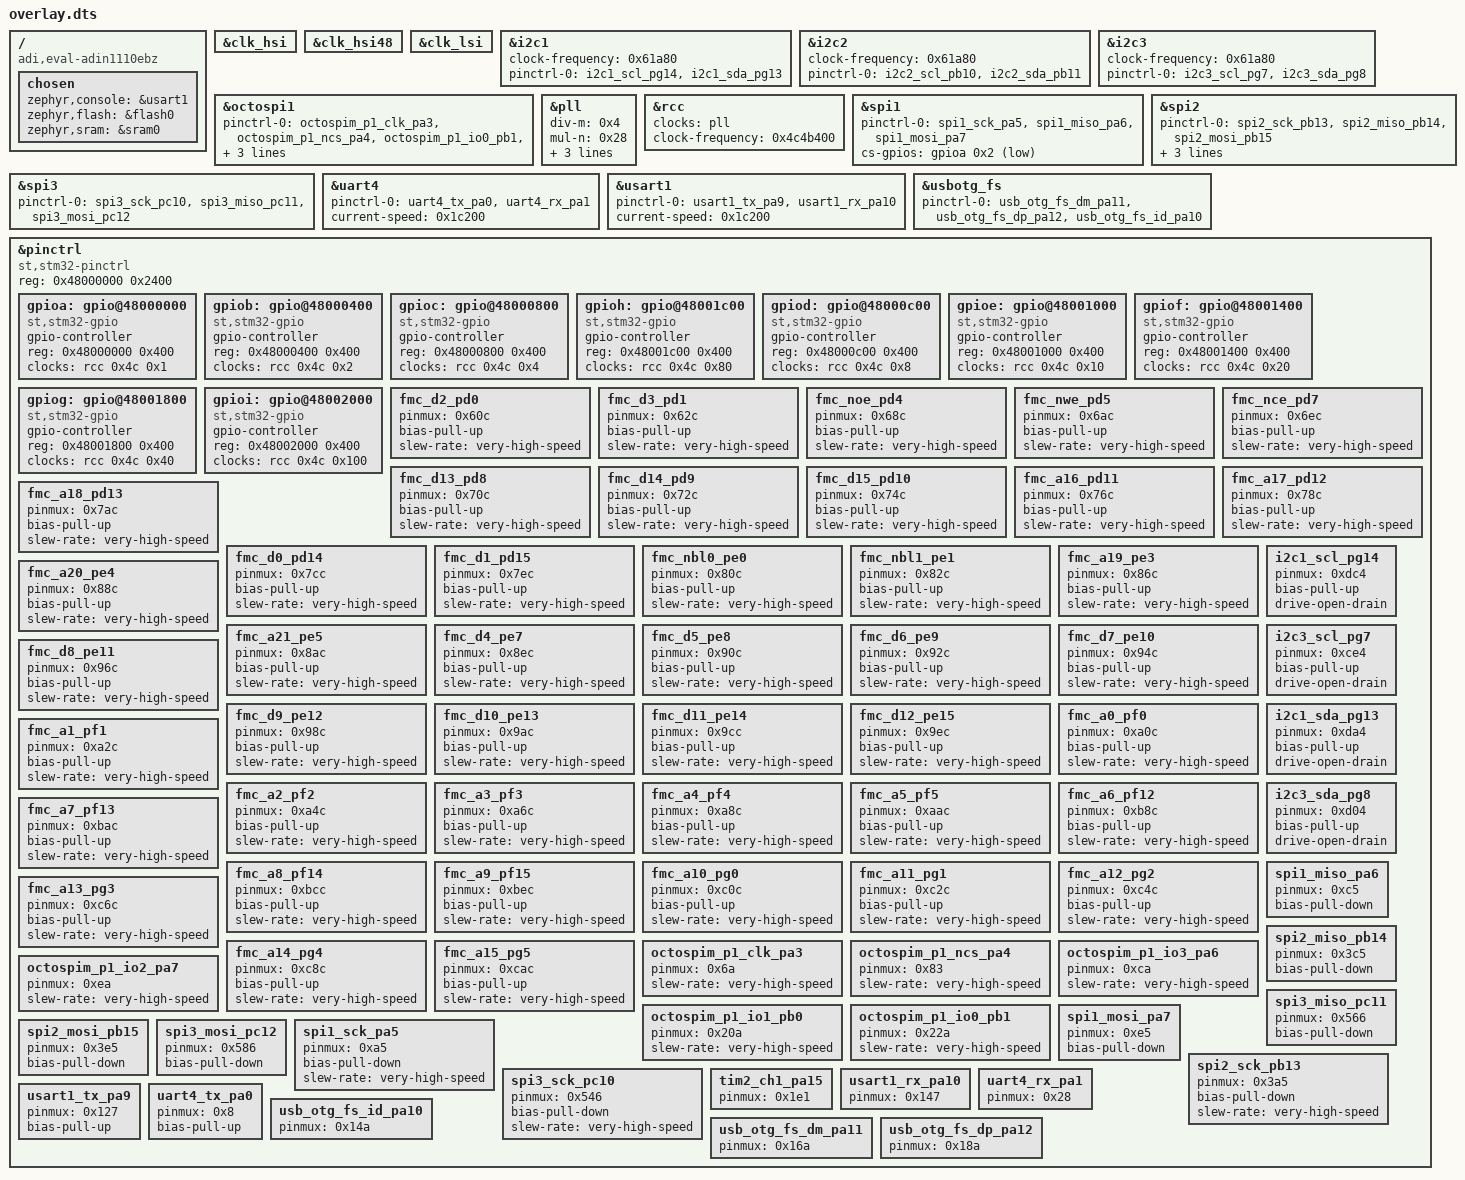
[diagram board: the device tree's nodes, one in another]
/ {
	compatible = "adi,eval-adin1110ebz";
	chosen {
		zephyr,console = &usart1;
		zephyr,flash = &flash0;
		zephyr,sram = &sram0;
	};
};
&clk_hsi{
	status = "okay";
};
&clk_hsi48{
	status = "okay";
};
&clk_lsi{
	status = "okay";
};
&i2c1{
	clock-frequency = < 0x61a80 >;
	status = "okay";
	pinctrl-0 = < &i2c1_scl_pg14 &i2c1_sda_pg13 >;
	pinctrl-names = "default";
};
&i2c2{
	clock-frequency = < 0x61a80 >;
	status = "okay";
	pinctrl-0 = < &i2c2_scl_pb10 &i2c2_sda_pb11 >;
	pinctrl-names = "default";
};
&i2c3{
	clock-frequency = < 0x61a80 >;
	status = "okay";
	pinctrl-0 = < &i2c3_scl_pg7 &i2c3_sda_pg8 >;
	pinctrl-names = "default";
};
&octospi1{
	status = "okay";
	pinctrl-0 = < &octospim_p1_clk_pa3 &octospim_p1_ncs_pa4 &octospim_p1_io0_pb1 &octospim_p1_io1_pb0 &octospim_p1_io2_pa7 &octospim_p1_io3_pa6 >;
	pinctrl-names = "default";
	dmas = < &dma1 0x0 0x28 0x480 >;
	dma-names = "tx_rx";
};
&pll{
	status = "okay";
	div-m = < 0x4 >;
	mul-n = < 0x28 >;
	div-q = < 0x2 >;
	div-r = < 0x2 >;
	clocks = < &clk_hsi >;
};
&rcc{
	clocks = < &pll >;
	clock-frequency = < 0x4c4b400 >;
};
&spi1{
	pinctrl-0 = < &spi1_sck_pa5 &spi1_miso_pa6 &spi1_mosi_pa7 >;
	pinctrl-names = "default";
	cs-gpios = < &gpioa 0x2 0x11 >;
};
&spi2{
	status = "okay";
	pinctrl-0 = < &spi2_sck_pb13 &spi2_miso_pb14 &spi2_mosi_pb15 >;
	pinctrl-names = "default";
	cs-gpios = < &gpiob 0xc 0x11 >;
	dmas = < &dmamux1 0x2 0xd 0x440 >, < &dmamux1 0x3 0xc 0x480 >;
	dma-names = "tx", "rx";
};
&spi3{
	status = "okay";
	pinctrl-0 = < &spi3_sck_pc10 &spi3_miso_pc11 &spi3_mosi_pc12 >;
	pinctrl-names = "default";
};
&uart4{
	pinctrl-0 = < &uart4_tx_pa0 &uart4_rx_pa1 >;
	pinctrl-names = "default";
	current-speed = < 0x1c200 >;
};
&usart1{
	status = "okay";
	pinctrl-0 = < &usart1_tx_pa9 &usart1_rx_pa10 >;
	pinctrl-names = "default";
	current-speed = < 0x1c200 >;
};
&usbotg_fs{
	status = "okay";
	pinctrl-0 = < &usb_otg_fs_dm_pa11 &usb_otg_fs_dp_pa12 &usb_otg_fs_id_pa10 >;
	pinctrl-names = "default";
};
&pinctrl{
	compatible = "st,stm32-pinctrl";
	#address-cells = < 0x1 >;
	#size-cells = < 0x1 >;
	reg = < 0x48000000 0x2400 >;
	gpioa: gpio@48000000 {
		compatible = "st,stm32-gpio";
		gpio-controller;
		#gpio-cells = < 0x2 >;
		reg = < 0x48000000 0x400 >;
		clocks = < &rcc 0x4c 0x1 >;
	};
	gpiob: gpio@48000400 {
		compatible = "st,stm32-gpio";
		gpio-controller;
		#gpio-cells = < 0x2 >;
		reg = < 0x48000400 0x400 >;
		clocks = < &rcc 0x4c 0x2 >;
	};
	gpioc: gpio@48000800 {
		compatible = "st,stm32-gpio";
		gpio-controller;
		#gpio-cells = < 0x2 >;
		reg = < 0x48000800 0x400 >;
		clocks = < &rcc 0x4c 0x4 >;
	};
	gpioh: gpio@48001c00 {
		compatible = "st,stm32-gpio";
		gpio-controller;
		#gpio-cells = < 0x2 >;
		reg = < 0x48001c00 0x400 >;
		clocks = < &rcc 0x4c 0x80 >;
	};
	gpiod: gpio@48000c00 {
		compatible = "st,stm32-gpio";
		gpio-controller;
		#gpio-cells = < 0x2 >;
		reg = < 0x48000c00 0x400 >;
		clocks = < &rcc 0x4c 0x8 >;
	};
	gpioe: gpio@48001000 {
		compatible = "st,stm32-gpio";
		gpio-controller;
		#gpio-cells = < 0x2 >;
		reg = < 0x48001000 0x400 >;
		clocks = < &rcc 0x4c 0x10 >;
	};
	gpiof: gpio@48001400 {
		compatible = "st,stm32-gpio";
		gpio-controller;
		#gpio-cells = < 0x2 >;
		reg = < 0x48001400 0x400 >;
		clocks = < &rcc 0x4c 0x20 >;
	};
	gpiog: gpio@48001800 {
		compatible = "st,stm32-gpio";
		gpio-controller;
		#gpio-cells = < 0x2 >;
		reg = < 0x48001800 0x400 >;
		clocks = < &rcc 0x4c 0x40 >;
	};
	gpioi: gpio@48002000 {
		compatible = "st,stm32-gpio";
		gpio-controller;
		#gpio-cells = < 0x2 >;
		reg = < 0x48002000 0x400 >;
		clocks = < &rcc 0x4c 0x100 >;
	};
	fmc_d2_pd0: fmc_d2_pd0 {
		pinmux = < 0x60c >;
		bias-pull-up;
		slew-rate = "very-high-speed";
	};
	fmc_d3_pd1: fmc_d3_pd1 {
		pinmux = < 0x62c >;
		bias-pull-up;
		slew-rate = "very-high-speed";
	};
	fmc_noe_pd4: fmc_noe_pd4 {
		pinmux = < 0x68c >;
		bias-pull-up;
		slew-rate = "very-high-speed";
	};
	fmc_nwe_pd5: fmc_nwe_pd5 {
		pinmux = < 0x6ac >;
		bias-pull-up;
		slew-rate = "very-high-speed";
	};
	fmc_nce_pd7: fmc_nce_pd7 {
		pinmux = < 0x6ec >;
		bias-pull-up;
		slew-rate = "very-high-speed";
	};
	fmc_d13_pd8: fmc_d13_pd8 {
		pinmux = < 0x70c >;
		bias-pull-up;
		slew-rate = "very-high-speed";
	};
	fmc_d14_pd9: fmc_d14_pd9 {
		pinmux = < 0x72c >;
		bias-pull-up;
		slew-rate = "very-high-speed";
	};
	fmc_d15_pd10: fmc_d15_pd10 {
		pinmux = < 0x74c >;
		bias-pull-up;
		slew-rate = "very-high-speed";
	};
	fmc_a16_pd11: fmc_a16_pd11 {
		pinmux = < 0x76c >;
		bias-pull-up;
		slew-rate = "very-high-speed";
	};
	fmc_a17_pd12: fmc_a17_pd12 {
		pinmux = < 0x78c >;
		bias-pull-up;
		slew-rate = "very-high-speed";
	};
	fmc_a18_pd13: fmc_a18_pd13 {
		pinmux = < 0x7ac >;
		bias-pull-up;
		slew-rate = "very-high-speed";
	};
	fmc_d0_pd14: fmc_d0_pd14 {
		pinmux = < 0x7cc >;
		bias-pull-up;
		slew-rate = "very-high-speed";
	};
	fmc_d1_pd15: fmc_d1_pd15 {
		pinmux = < 0x7ec >;
		bias-pull-up;
		slew-rate = "very-high-speed";
	};
	fmc_nbl0_pe0: fmc_nbl0_pe0 {
		pinmux = < 0x80c >;
		bias-pull-up;
		slew-rate = "very-high-speed";
	};
	fmc_nbl1_pe1: fmc_nbl1_pe1 {
		pinmux = < 0x82c >;
		bias-pull-up;
		slew-rate = "very-high-speed";
	};
	fmc_a19_pe3: fmc_a19_pe3 {
		pinmux = < 0x86c >;
		bias-pull-up;
		slew-rate = "very-high-speed";
	};
	fmc_a20_pe4: fmc_a20_pe4 {
		pinmux = < 0x88c >;
		bias-pull-up;
		slew-rate = "very-high-speed";
	};
	fmc_a21_pe5: fmc_a21_pe5 {
		pinmux = < 0x8ac >;
		bias-pull-up;
		slew-rate = "very-high-speed";
	};
	fmc_d4_pe7: fmc_d4_pe7 {
		pinmux = < 0x8ec >;
		bias-pull-up;
		slew-rate = "very-high-speed";
	};
	fmc_d5_pe8: fmc_d5_pe8 {
		pinmux = < 0x90c >;
		bias-pull-up;
		slew-rate = "very-high-speed";
	};
	fmc_d6_pe9: fmc_d6_pe9 {
		pinmux = < 0x92c >;
		bias-pull-up;
		slew-rate = "very-high-speed";
	};
	fmc_d7_pe10: fmc_d7_pe10 {
		pinmux = < 0x94c >;
		bias-pull-up;
		slew-rate = "very-high-speed";
	};
	fmc_d8_pe11: fmc_d8_pe11 {
		pinmux = < 0x96c >;
		bias-pull-up;
		slew-rate = "very-high-speed";
	};
	fmc_d9_pe12: fmc_d9_pe12 {
		pinmux = < 0x98c >;
		bias-pull-up;
		slew-rate = "very-high-speed";
	};
	fmc_d10_pe13: fmc_d10_pe13 {
		pinmux = < 0x9ac >;
		bias-pull-up;
		slew-rate = "very-high-speed";
	};
	fmc_d11_pe14: fmc_d11_pe14 {
		pinmux = < 0x9cc >;
		bias-pull-up;
		slew-rate = "very-high-speed";
	};
	fmc_d12_pe15: fmc_d12_pe15 {
		pinmux = < 0x9ec >;
		bias-pull-up;
		slew-rate = "very-high-speed";
	};
	fmc_a0_pf0: fmc_a0_pf0 {
		pinmux = < 0xa0c >;
		bias-pull-up;
		slew-rate = "very-high-speed";
	};
	fmc_a1_pf1: fmc_a1_pf1 {
		pinmux = < 0xa2c >;
		bias-pull-up;
		slew-rate = "very-high-speed";
	};
	fmc_a2_pf2: fmc_a2_pf2 {
		pinmux = < 0xa4c >;
		bias-pull-up;
		slew-rate = "very-high-speed";
	};
	fmc_a3_pf3: fmc_a3_pf3 {
		pinmux = < 0xa6c >;
		bias-pull-up;
		slew-rate = "very-high-speed";
	};
	fmc_a4_pf4: fmc_a4_pf4 {
		pinmux = < 0xa8c >;
		bias-pull-up;
		slew-rate = "very-high-speed";
	};
	fmc_a5_pf5: fmc_a5_pf5 {
		pinmux = < 0xaac >;
		bias-pull-up;
		slew-rate = "very-high-speed";
	};
	fmc_a6_pf12: fmc_a6_pf12 {
		pinmux = < 0xb8c >;
		bias-pull-up;
		slew-rate = "very-high-speed";
	};
	fmc_a7_pf13: fmc_a7_pf13 {
		pinmux = < 0xbac >;
		bias-pull-up;
		slew-rate = "very-high-speed";
	};
	fmc_a8_pf14: fmc_a8_pf14 {
		pinmux = < 0xbcc >;
		bias-pull-up;
		slew-rate = "very-high-speed";
	};
	fmc_a9_pf15: fmc_a9_pf15 {
		pinmux = < 0xbec >;
		bias-pull-up;
		slew-rate = "very-high-speed";
	};
	fmc_a10_pg0: fmc_a10_pg0 {
		pinmux = < 0xc0c >;
		bias-pull-up;
		slew-rate = "very-high-speed";
	};
	fmc_a11_pg1: fmc_a11_pg1 {
		pinmux = < 0xc2c >;
		bias-pull-up;
		slew-rate = "very-high-speed";
	};
	fmc_a12_pg2: fmc_a12_pg2 {
		pinmux = < 0xc4c >;
		bias-pull-up;
		slew-rate = "very-high-speed";
	};
	fmc_a13_pg3: fmc_a13_pg3 {
		pinmux = < 0xc6c >;
		bias-pull-up;
		slew-rate = "very-high-speed";
	};
	fmc_a14_pg4: fmc_a14_pg4 {
		pinmux = < 0xc8c >;
		bias-pull-up;
		slew-rate = "very-high-speed";
	};
	fmc_a15_pg5: fmc_a15_pg5 {
		pinmux = < 0xcac >;
		bias-pull-up;
		slew-rate = "very-high-speed";
	};
	i2c1_scl_pg14: i2c1_scl_pg14 {
		pinmux = < 0xdc4 >;
		bias-pull-up;
		drive-open-drain;
	};
	i2c3_scl_pg7: i2c3_scl_pg7 {
		pinmux = < 0xce4 >;
		bias-pull-up;
		drive-open-drain;
	};
	i2c1_sda_pg13: i2c1_sda_pg13 {
		pinmux = < 0xda4 >;
		bias-pull-up;
		drive-open-drain;
	};
	i2c3_sda_pg8: i2c3_sda_pg8 {
		pinmux = < 0xd04 >;
		bias-pull-up;
		drive-open-drain;
	};
	octospim_p1_clk_pa3: octospim_p1_clk_pa3 {
		pinmux = < 0x6a >;
		slew-rate = "very-high-speed";
	};
	octospim_p1_ncs_pa4: octospim_p1_ncs_pa4 {
		pinmux = < 0x83 >;
		slew-rate = "very-high-speed";
	};
	octospim_p1_io3_pa6: octospim_p1_io3_pa6 {
		pinmux = < 0xca >;
		slew-rate = "very-high-speed";
	};
	octospim_p1_io2_pa7: octospim_p1_io2_pa7 {
		pinmux = < 0xea >;
		slew-rate = "very-high-speed";
	};
	octospim_p1_io1_pb0: octospim_p1_io1_pb0 {
		pinmux = < 0x20a >;
		slew-rate = "very-high-speed";
	};
	octospim_p1_io0_pb1: octospim_p1_io0_pb1 {
		pinmux = < 0x22a >;
		slew-rate = "very-high-speed";
	};
	spi1_miso_pa6: spi1_miso_pa6 {
		pinmux = < 0xc5 >;
		bias-pull-down;
	};
	spi2_miso_pb14: spi2_miso_pb14 {
		pinmux = < 0x3c5 >;
		bias-pull-down;
	};
	spi3_miso_pc11: spi3_miso_pc11 {
		pinmux = < 0x566 >;
		bias-pull-down;
	};
	spi1_mosi_pa7: spi1_mosi_pa7 {
		pinmux = < 0xe5 >;
		bias-pull-down;
	};
	spi2_mosi_pb15: spi2_mosi_pb15 {
		pinmux = < 0x3e5 >;
		bias-pull-down;
	};
	spi3_mosi_pc12: spi3_mosi_pc12 {
		pinmux = < 0x586 >;
		bias-pull-down;
	};
	spi1_sck_pa5: spi1_sck_pa5 {
		pinmux = < 0xa5 >;
		bias-pull-down;
		slew-rate = "very-high-speed";
	};
	spi2_sck_pb13: spi2_sck_pb13 {
		pinmux = < 0x3a5 >;
		bias-pull-down;
		slew-rate = "very-high-speed";
	};
	spi3_sck_pc10: spi3_sck_pc10 {
		pinmux = < 0x546 >;
		bias-pull-down;
		slew-rate = "very-high-speed";
	};
	tim2_ch1_pa15: tim2_ch1_pa15 {
		pinmux = < 0x1e1 >;
	};
	usart1_rx_pa10: usart1_rx_pa10 {
		pinmux = < 0x147 >;
	};
	uart4_rx_pa1: uart4_rx_pa1 {
		pinmux = < 0x28 >;
	};
	usart1_tx_pa9: usart1_tx_pa9 {
		pinmux = < 0x127 >;
		bias-pull-up;
	};
	uart4_tx_pa0: uart4_tx_pa0 {
		pinmux = < 0x8 >;
		bias-pull-up;
	};
	usb_otg_fs_id_pa10: usb_otg_fs_id_pa10 {
		pinmux = < 0x14a >;
	};
	usb_otg_fs_dm_pa11: usb_otg_fs_dm_pa11 {
		pinmux = < 0x16a >;
	};
	usb_otg_fs_dp_pa12: usb_otg_fs_dp_pa12 {
		pinmux = < 0x18a >;
	};
};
